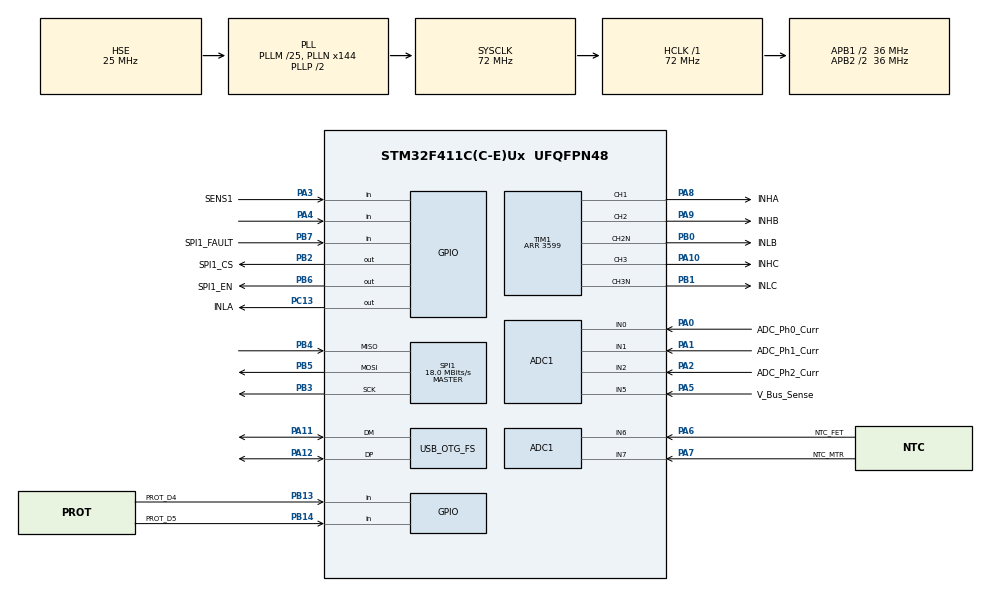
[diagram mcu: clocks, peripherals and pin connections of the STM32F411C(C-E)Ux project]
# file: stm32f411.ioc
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ADC1.Channel-0\#ChannelRegularConversion=ADC_CHANNEL_0
ADC1.Channel-1\#ChannelRegularConversion=ADC_CHANNEL_1
ADC1.Channel-2\#ChannelRegularConversion=ADC_CHANNEL_2
ADC1.Channel-3\#ChannelRegularConversion=ADC_CHANNEL_5
ADC1.Channel-4\#ChannelRegularConversion=ADC_CHANNEL_6
ADC1.Channel-5\#ChannelRegularConversion=ADC_CHANNEL_7
ADC1.ClockPrescaler=ADC_CLOCK_SYNC_PCLK_DIV4
ADC1.ContinuousConvMode=ENABLE
ADC1.DMAContinuousRequests=ENABLE
ADC1.EOCSelection=ADC_EOC_SEQ_CONV
ADC1.NbrOfConversion=6
ADC1.NbrOfConversionFlag=1
ADC1.Rank-0\#ChannelRegularConversion=1
ADC1.Rank-1\#ChannelRegularConversion=2
ADC1.Rank-2\#ChannelRegularConversion=3
ADC1.Rank-3\#ChannelRegularConversion=4
ADC1.Rank-4\#ChannelRegularConversion=5
ADC1.Rank-5\#ChannelRegularConversion=6
ADC1.SamplingTime-0\#ChannelRegularConversion=ADC_SAMPLETIME_84CYCLES
ADC1.SamplingTime-1\#ChannelRegularConversion=ADC_SAMPLETIME_84CYCLES
ADC1.SamplingTime-2\#ChannelRegularConversion=ADC_SAMPLETIME_84CYCLES
ADC1.SamplingTime-3\#ChannelRegularConversion=ADC_SAMPLETIME_84CYCLES
ADC1.SamplingTime-4\#ChannelRegularConversion=ADC_SAMPLETIME_84CYCLES
ADC1.SamplingTime-5\#ChannelRegularConversion=ADC_SAMPLETIME_84CYCLES
ADC1.ScanConvMode=ENABLE
ADC1.master=1
Dma.ADC1.0.Direction=DMA_PERIPH_TO_MEMORY
Dma.ADC1.0.FIFOMode=DMA_FIFOMODE_DISABLE
Dma.ADC1.0.Instance=DMA2_Stream0
Dma.ADC1.0.MemDataAlignment=DMA_MDATAALIGN_HALFWORD
Dma.ADC1.0.MemInc=DMA_MINC_ENABLE
Dma.ADC1.0.Mode=DMA_CIRCULAR
Dma.ADC1.0.PeriphDataAlignment=DMA_PDATAALIGN_HALFWORD
Dma.ADC1.0.PeriphInc=DMA_PINC_DISABLE
Dma.ADC1.0.Priority=DMA_PRIORITY_HIGH
Dma.Request0=ADC1
FREERTOS.Tasks01=defaultTask,24,512,StartDefaultTask,Default,NULL,Dynamic,NULL,NULL;telemTask,8,512,TelemThread,As external,NULL,Dynamic,NULL,NULL;commTask,32,1024,CommThread,As external,NULL,Dynamic,NULL,NULL
Mcu.Family=STM32F4
Mcu.Name=STM32F411C(C-E)Ux
Mcu.Package=UFQFPN48
NVIC.DMA2_Stream0_IRQn=true\:5\:0\:false\:false\:true\:true\:false\:true\:true
NVIC.OTG_FS_IRQn=true\:5\:0\:false\:false\:true\:true\:false\:true\:true
NVIC.PriorityGroup=NVIC_PRIORITYGROUP_4
NVIC.TIM5_IRQn=true\:15\:0\:false\:false\:true\:false\:false\:true\:true
NVIC.TimeBase=TIM5_IRQn
NVIC.TimeBaseIP=TIM5
PA0-WKUP.GPIO_Label=ADC_Ph0_Curr
PA0-WKUP.Signal=ADCx_IN0
PA1.GPIO_Label=ADC_Ph1_Curr
PA1.Signal=ADCx_IN1
PA10.GPIO_Label=INHC
PA10.Signal=S_TIM1_CH3
PA11.Mode=Device_Only
PA11.Signal=USB_OTG_FS_DM
PA12.Mode=Device_Only
PA12.Signal=USB_OTG_FS_DP
PA13.Mode=Serial_Wire
PA13.Signal=SYS_JTMS-SWDIO
PA14.Mode=Serial_Wire
PA14.Signal=SYS_JTCK-SWCLK
PA2.GPIO_Label=ADC_Ph2_Curr
PA2.Signal=ADCx_IN2
PA3.GPIO_Label=SENS1
PA3.Signal=GPIO_Input
PA4.Signal=GPIO_Input
PA5.GPIO_Label=V_Bus_Sense
PA5.Signal=ADCx_IN5
PA6.GPIO_Label=NTC_FET
PA6.Signal=ADCx_IN6
PA7.GPIO_Label=NTC_MTR
PA7.Signal=ADCx_IN7
PA8.GPIO_Label=INHA
PA8.Signal=S_TIM1_CH1
PA9.GPIO_Label=INHB
PA9.Signal=S_TIM1_CH2
PB0.GPIO_Label=INLB
PB0.Mode=PWM Generation2 CH2 CH2N
PB0.Signal=TIM1_CH2N
PB1.GPIO_Label=INLC
PB1.Mode=PWM Generation3 CH3 CH3N
PB1.Signal=TIM1_CH3N
PB13.GPIO_Label=PROT_D4
PB13.Signal=GPIO_Input
PB14.GPIO_Label=PROT_D5
PB14.Signal=GPIO_Input
PB2.GPIO_Label=SPI1_CS
PB2.GPIO_Speed=GPIO_SPEED_FREQ_VERY_HIGH
PB2.Signal=GPIO_Output
PB3.Mode=Full_Duplex_Master
PB3.Signal=SPI1_SCK
PB4.Mode=Full_Duplex_Master
PB4.Signal=SPI1_MISO
PB5.Mode=Full_Duplex_Master
PB5.Signal=SPI1_MOSI
PB6.GPIO_Label=SPI1_EN
PB6.GPIO_Speed=GPIO_SPEED_FREQ_VERY_HIGH
PB6.Signal=GPIO_Output
PB7.GPIO_Label=SPI1_FAULT
PB7.Signal=GPIO_Input
PC13-ANTI_TAMP.GPIO_Label=INLA
PC13-ANTI_TAMP.GPIO_Speed=GPIO_SPEED_FREQ_HIGH
PC13-ANTI_TAMP.Signal=GPIO_Output
PH0\ -\ OSC_IN.Mode=HSE-External-Oscillator
PH0\ -\ OSC_IN.Signal=RCC_OSC_IN
PH1\ -\ OSC_OUT.Mode=HSE-External-Oscillator
PH1\ -\ OSC_OUT.Signal=RCC_OSC_OUT
ProjectManager.HeapSize=0x200
ProjectManager.StackSize=0x400
ProjectManager.TargetToolchain=CMake
RCC.48MHZClocksFreq_Value=48000000
RCC.AHBFreq_Value=72000000
RCC.APB1CLKDivider=RCC_HCLK_DIV2
RCC.APB1Freq_Value=36000000
RCC.APB1TimFreq_Value=72000000
RCC.APB2CLKDivider=RCC_HCLK_DIV2
RCC.APB2Freq_Value=36000000
RCC.APB2TimFreq_Value=72000000
RCC.CortexFreq_Value=72000000
RCC.HCLKFreq_Value=72000000
RCC.HSE_VALUE=25000000
RCC.HSI_VALUE=16000000
RCC.LSE_VALUE=32768
RCC.PLLM=25
RCC.PLLN=144
RCC.PLLQ=3
RCC.SYSCLKFreq_VALUE=72000000
RCC.SYSCLKSource=RCC_SYSCLKSOURCE_PLLCLK
RCC.VCOOutputFreq_Value=144000000
SH.ADCx_IN0.0=ADC1_IN0,IN0
SH.ADCx_IN1.0=ADC1_IN1,IN1
SH.ADCx_IN2.0=ADC1_IN2,IN2
SH.ADCx_IN5.0=ADC1_IN5,IN5
SH.ADCx_IN6.0=ADC1_IN6,IN6
SH.ADCx_IN7.0=ADC1_IN7,IN7
SH.S_TIM1_CH1.0=TIM1_CH1,PWM Generation1 CH1
SH.S_TIM1_CH2.0=TIM1_CH2,PWM Generation2 CH2 CH2N
SH.S_TIM1_CH3.0=TIM1_CH3,PWM Generation3 CH3 CH3N
SPI1.CalculateBaudRate=18.0 MBits/s
SPI1.Direction=SPI_DIRECTION_2LINES
SPI1.Mode=SPI_MODE_MASTER
SPI1.VirtualType=VM_MASTER
TIM1.Channel-PWM\ Generation1\ CH1=TIM_CHANNEL_1
TIM1.Channel-PWM\ Generation2\ CH2\ CH2N=TIM_CHANNEL_2
TIM1.Channel-PWM\ Generation3\ CH3\ CH3N=TIM_CHANNEL_3
TIM1.Period=3599
TIM1.TIM_MasterOutputTrigger=TIM_TRGO_RESET
TIM1.TIM_MasterSlaveMode=TIM_MASTERSLAVEMODE_DISABLE
USB_DEVICE.CLASS_NAME_FS=CDC
USB_DEVICE.VirtualMode=Cdc
USB_DEVICE.VirtualModeFS=Cdc_FS
USB_OTG_FS.VirtualMode=Device_Only
VP_CRC_VS_CRC.Mode=CRC_Activate
VP_FREERTOS_VS_CMSIS_V2.Mode=CMSIS_V2
VP_SYS_VS_tim5.Mode=TIM5
VP_USB_DEVICE_VS_USB_DEVICE_CDC_FS.Mode=CDC_FS
board=custom

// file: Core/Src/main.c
/* USER CODE BEGIN Header */
/**
  ******************************************************************************
  * @file           : main.c
  * @brief          : Main program body
  ******************************************************************************
  * @attention
  *
  * Copyright (c) 2026 STMicroelectronics.
  * All rights reserved.
  *
  * This software is licensed under terms that can be found in the LICENSE file
  * in the root directory of this software component.
  * If no LICENSE file comes with this software, it is provided AS-IS.
  *
  ******************************************************************************
  */
/* USER CODE END Header */
#include "main.h"
#include "cmsis_os.h"
#include "usb_device.h"

/* USER CODE BEGIN Includes */
#include "bsp.h"
/* USER CODE END Includes */

ADC_HandleTypeDef hadc1;
DMA_HandleTypeDef hdma_adc1;

CRC_HandleTypeDef hcrc;

SPI_HandleTypeDef hspi1;

TIM_HandleTypeDef htim1;

/* Definitions for defaultTask */
osThreadId_t defaultTaskHandle;
const osThreadAttr_t defaultTask_attributes = {
  .name = "defaultTask",
  .stack_size = 512 * 4,
  .priority = (osPriority_t) osPriorityNormal,
};
/* Definitions for telemTask */
osThreadId_t telemTaskHandle;
const osThreadAttr_t telemTask_attributes = {
  .name = "telemTask",
  .stack_size = 512 * 4,
  .priority = (osPriority_t) osPriorityLow,
};
/* Definitions for commTask */
osThreadId_t commTaskHandle;
const osThreadAttr_t commTask_attributes = {
  .name = "commTask",
  .stack_size = 1024 * 4,
  .priority = (osPriority_t) osPriorityAboveNormal,
};

void SystemClock_Config(void);
static void MX_GPIO_Init(void);
static void MX_DMA_Init(void);
static void MX_TIM1_Init(void);
static void MX_ADC1_Init(void);
static void MX_SPI1_Init(void);
static void MX_CRC_Init(void);
void StartDefaultTask(void *argument);
extern void TelemThread(void *argument);
extern void CommThread(void *argument);

int main(void)
{

  /* MCU Configuration--------------------------------------------------------*/

  /* Reset of all peripherals, Initializes the Flash interface and the Systick. */
  HAL_Init();

  /* Configure the system clock */
  SystemClock_Config();

  /* Initialize all configured peripherals */
  MX_GPIO_Init();
  MX_DMA_Init();
  MX_TIM1_Init();
  MX_ADC1_Init();
  MX_SPI1_Init();
  MX_CRC_Init();
  /* USER CODE BEGIN 2 */
	bsp_init();
	bldc_comm_init(bsp_get_motor_handle());
  bldc_telem_init();
  // bldc_dronecan_init();
  // bldc_drv8323r_init();
  /* USER CODE END 2 */

  /* Init scheduler */
  osKernelInitialize();

  /* Create the thread(s) */
  /* creation of defaultTask */
  defaultTaskHandle = osThreadNew(StartDefaultTask, NULL, &defaultTask_attributes);

  /* creation of telemTask */
  telemTaskHandle = osThreadNew(TelemThread, NULL, &telemTask_attributes);

  /* creation of commTask */
  commTaskHandle = osThreadNew(CommThread, NULL, &commTask_attributes);

  /* Start scheduler */
  osKernelStart();

  /* We should never get here as control is now taken by the scheduler */

  /* Infinite loop */
  while (1)
  {

  }
}

void SystemClock_Config(void)
{
  RCC_OscInitTypeDef RCC_OscInitStruct = {0};
  RCC_ClkInitTypeDef RCC_ClkInitStruct = {0};

  /** Configure the main internal regulator output voltage
  */
  __HAL_RCC_PWR_CLK_ENABLE();
  __HAL_PWR_VOLTAGESCALING_CONFIG(PWR_REGULATOR_VOLTAGE_SCALE1);

  /** Initializes the RCC Oscillators according to the specified parameters
  * in the RCC_OscInitTypeDef structure.
  */
  RCC_OscInitStruct.OscillatorType = RCC_OSCILLATORTYPE_HSE;
  RCC_OscInitStruct.HSEState = RCC_HSE_ON;
  RCC_OscInitStruct.PLL.PLLState = RCC_PLL_ON;
  RCC_OscInitStruct.PLL.PLLSource = RCC_PLLSOURCE_HSE;
  RCC_OscInitStruct.PLL.PLLM = 25;
  RCC_OscInitStruct.PLL.PLLN = 144;
  RCC_OscInitStruct.PLL.PLLP = RCC_PLLP_DIV2;
  RCC_OscInitStruct.PLL.PLLQ = 3;
  if (HAL_RCC_OscConfig(&RCC_OscInitStruct) != HAL_OK)
  {
    Error_Handler();
  }

  /** Initializes the CPU, AHB and APB buses clocks
  */
  RCC_ClkInitStruct.ClockType = RCC_CLOCKTYPE_HCLK|RCC_CLOCKTYPE_SYSCLK
                              |RCC_CLOCKTYPE_PCLK1|RCC_CLOCKTYPE_PCLK2;
  RCC_ClkInitStruct.SYSCLKSource = RCC_SYSCLKSOURCE_PLLCLK;
  RCC_ClkInitStruct.AHBCLKDivider = RCC_SYSCLK_DIV1;
  RCC_ClkInitStruct.APB1CLKDivider = RCC_HCLK_DIV2;
  RCC_ClkInitStruct.APB2CLKDivider = RCC_HCLK_DIV2;

  if (HAL_RCC_ClockConfig(&RCC_ClkInitStruct, FLASH_LATENCY_2) != HAL_OK)
  {
    Error_Handler();
  }
}

static void MX_ADC1_Init(void)
{

  ADC_ChannelConfTypeDef sConfig = {0};

  /** Configure the global features of the ADC (Clock, Resolution, Data Alignment and number of conversion)
  */
  hadc1.Instance = ADC1;
  hadc1.Init.ClockPrescaler = ADC_CLOCK_SYNC_PCLK_DIV4;
  hadc1.Init.Resolution = ADC_RESOLUTION_12B;
  hadc1.Init.ScanConvMode = ENABLE;
  hadc1.Init.ContinuousConvMode = ENABLE;
  hadc1.Init.DiscontinuousConvMode = DISABLE;
  hadc1.Init.ExternalTrigConvEdge = ADC_EXTERNALTRIGCONVEDGE_NONE;
  hadc1.Init.ExternalTrigConv = ADC_SOFTWARE_START;
  hadc1.Init.DataAlign = ADC_DATAALIGN_RIGHT;
  hadc1.Init.NbrOfConversion = 6;
  hadc1.Init.DMAContinuousRequests = ENABLE;
  hadc1.Init.EOCSelection = ADC_EOC_SEQ_CONV;
  if (HAL_ADC_Init(&hadc1) != HAL_OK)
  {
    Error_Handler();
  }

  /** Configure for the selected ADC regular channel its corresponding rank in the sequencer and its sample time.
  */
  sConfig.Channel = ADC_CHANNEL_0;
  sConfig.Rank = 1;
  sConfig.SamplingTime = ADC_SAMPLETIME_84CYCLES;
  if (HAL_ADC_ConfigChannel(&hadc1, &sConfig) != HAL_OK)
  {
    Error_Handler();
  }

  /** Configure for the selected ADC regular channel its corresponding rank in the sequencer and its sample time.
  */
  sConfig.Channel = ADC_CHANNEL_1;
  sConfig.Rank = 2;
  if (HAL_ADC_ConfigChannel(&hadc1, &sConfig) != HAL_OK)
  {
    Error_Handler();
  }

  /** Configure for the selected ADC regular channel its corresponding rank in the sequencer and its sample time.
  */
  sConfig.Channel = ADC_CHANNEL_2;
  sConfig.Rank = 3;
  if (HAL_ADC_ConfigChannel(&hadc1, &sConfig) != HAL_OK)
  {
    Error_Handler();
  }

  /** Configure for the selected ADC regular channel its corresponding rank in the sequencer and its sample time.
  */
  sConfig.Channel = ADC_CHANNEL_5;
  sConfig.Rank = 4;
  if (HAL_ADC_ConfigChannel(&hadc1, &sConfig) != HAL_OK)
  {
    Error_Handler();
  }

  /** Configure for the selected ADC regular channel its corresponding rank in the sequencer and its sample time.
  */
  sConfig.Channel = ADC_CHANNEL_6;
  sConfig.Rank = 5;
  if (HAL_ADC_ConfigChannel(&hadc1, &sConfig) != HAL_OK)
  {
    Error_Handler();
  }

  /** Configure for the selected ADC regular channel its corresponding rank in the sequencer and its sample time.
  */
  sConfig.Channel = ADC_CHANNEL_7;
  sConfig.Rank = 6;
  if (HAL_ADC_ConfigChannel(&hadc1, &sConfig) != HAL_OK)
  {
    Error_Handler();
  }

}

static void MX_CRC_Init(void)
{

  hcrc.Instance = CRC;
  if (HAL_CRC_Init(&hcrc) != HAL_OK)
  {
    Error_Handler();
  }

}

static void MX_SPI1_Init(void)
{

  /* SPI1 parameter configuration*/
  hspi1.Instance = SPI1;
  hspi1.Init.Mode = SPI_MODE_MASTER;
  hspi1.Init.Direction = SPI_DIRECTION_2LINES;
  hspi1.Init.DataSize = SPI_DATASIZE_8BIT;
  hspi1.Init.CLKPolarity = SPI_POLARITY_LOW;
  hspi1.Init.CLKPhase = SPI_PHASE_1EDGE;
  hspi1.Init.NSS = SPI_NSS_SOFT;
  hspi1.Init.BaudRatePrescaler = SPI_BAUDRATEPRESCALER_2;
  hspi1.Init.FirstBit = SPI_FIRSTBIT_MSB;
  hspi1.Init.TIMode = SPI_TIMODE_DISABLE;
  hspi1.Init.CRCCalculation = SPI_CRCCALCULATION_DISABLE;
  hspi1.Init.CRCPolynomial = 10;
  if (HAL_SPI_Init(&hspi1) != HAL_OK)
  {
    Error_Handler();
  }

}

static void MX_TIM1_Init(void)
{

  TIM_MasterConfigTypeDef sMasterConfig = {0};
  TIM_OC_InitTypeDef sConfigOC = {0};
  TIM_BreakDeadTimeConfigTypeDef sBreakDeadTimeConfig = {0};

  htim1.Instance = TIM1;
  htim1.Init.Prescaler = 0;
  htim1.Init.CounterMode = TIM_COUNTERMODE_UP;
  htim1.Init.Period = 3599;
  htim1.Init.ClockDivision = TIM_CLOCKDIVISION_DIV1;
  htim1.Init.RepetitionCounter = 0;
  htim1.Init.AutoReloadPreload = TIM_AUTORELOAD_PRELOAD_DISABLE;
  if (HAL_TIM_PWM_Init(&htim1) != HAL_OK)
  {
    Error_Handler();
  }
  sMasterConfig.MasterOutputTrigger = TIM_TRGO_RESET;
  sMasterConfig.MasterSlaveMode = TIM_MASTERSLAVEMODE_DISABLE;
  if (HAL_TIMEx_MasterConfigSynchronization(&htim1, &sMasterConfig) != HAL_OK)
  {
    Error_Handler();
  }
  sConfigOC.OCMode = TIM_OCMODE_PWM1;
  sConfigOC.Pulse = 0;
  sConfigOC.OCPolarity = TIM_OCPOLARITY_HIGH;
  sConfigOC.OCNPolarity = TIM_OCNPOLARITY_HIGH;
  sConfigOC.OCFastMode = TIM_OCFAST_DISABLE;
  sConfigOC.OCIdleState = TIM_OCIDLESTATE_RESET;
  sConfigOC.OCNIdleState = TIM_OCNIDLESTATE_RESET;
  if (HAL_TIM_PWM_ConfigChannel(&htim1, &sConfigOC, TIM_CHANNEL_1) != HAL_OK)
  {
    Error_Handler();
  }
  if (HAL_TIM_PWM_ConfigChannel(&htim1, &sConfigOC, TIM_CHANNEL_2) != HAL_OK)
  {
    Error_Handler();
  }
  if (HAL_TIM_PWM_ConfigChannel(&htim1, &sConfigOC, TIM_CHANNEL_3) != HAL_OK)
  {
    Error_Handler();
  }
  sBreakDeadTimeConfig.OffStateRunMode = TIM_OSSR_DISABLE;
  sBreakDeadTimeConfig.OffStateIDLEMode = TIM_OSSI_DISABLE;
  sBreakDeadTimeConfig.LockLevel = TIM_LOCKLEVEL_OFF;
  sBreakDeadTimeConfig.DeadTime = 0;
  sBreakDeadTimeConfig.BreakState = TIM_BREAK_DISABLE;
  sBreakDeadTimeConfig.BreakPolarity = TIM_BREAKPOLARITY_HIGH;
  sBreakDeadTimeConfig.AutomaticOutput = TIM_AUTOMATICOUTPUT_DISABLE;
  if (HAL_TIMEx_ConfigBreakDeadTime(&htim1, &sBreakDeadTimeConfig) != HAL_OK)
  {
    Error_Handler();
  }
  HAL_TIM_MspPostInit(&htim1);

}

static void MX_DMA_Init(void)
{

  /* DMA controller clock enable */
  __HAL_RCC_DMA2_CLK_ENABLE();

  /* DMA interrupt init */
  /* DMA2_Stream0_IRQn interrupt configuration */
  HAL_NVIC_SetPriority(DMA2_Stream0_IRQn, 5, 0);
  HAL_NVIC_EnableIRQ(DMA2_Stream0_IRQn);

}

static void MX_GPIO_Init(void)
{
  GPIO_InitTypeDef GPIO_InitStruct = {0};

  /* GPIO Ports Clock Enable */
  __HAL_RCC_GPIOC_CLK_ENABLE();
  __HAL_RCC_GPIOH_CLK_ENABLE();
  __HAL_RCC_GPIOA_CLK_ENABLE();
  __HAL_RCC_GPIOB_CLK_ENABLE();

  /*Configure GPIO pin Output Level */
  HAL_GPIO_WritePin(INLA_GPIO_Port, INLA_Pin, GPIO_PIN_RESET);

  /*Configure GPIO pin Output Level */
  HAL_GPIO_WritePin(GPIOB, SPI1_CS_Pin|SPI1_EN_Pin, GPIO_PIN_RESET);

  /*Configure GPIO pin : INLA_Pin */
  GPIO_InitStruct.Pin = INLA_Pin;
  GPIO_InitStruct.Mode = GPIO_MODE_OUTPUT_PP;
  GPIO_InitStruct.Pull = GPIO_NOPULL;
  GPIO_InitStruct.Speed = GPIO_SPEED_FREQ_HIGH;
  HAL_GPIO_Init(INLA_GPIO_Port, &GPIO_InitStruct);

  /*Configure GPIO pins : SENS1_Pin PA4 */
  GPIO_InitStruct.Pin = SENS1_Pin|GPIO_PIN_4;
  GPIO_InitStruct.Mode = GPIO_MODE_INPUT;
  GPIO_InitStruct.Pull = GPIO_NOPULL;
  HAL_GPIO_Init(GPIOA, &GPIO_InitStruct);

  /*Configure GPIO pins : SPI1_CS_Pin SPI1_EN_Pin */
  GPIO_InitStruct.Pin = SPI1_CS_Pin|SPI1_EN_Pin;
  GPIO_InitStruct.Mode = GPIO_MODE_OUTPUT_PP;
  GPIO_InitStruct.Pull = GPIO_NOPULL;
  GPIO_InitStruct.Speed = GPIO_SPEED_FREQ_VERY_HIGH;
  HAL_GPIO_Init(GPIOB, &GPIO_InitStruct);

  /*Configure GPIO pins : PROT_D4_Pin PROT_D5_Pin SPI1_FAULT_Pin */
  GPIO_InitStruct.Pin = PROT_D4_Pin|PROT_D5_Pin|SPI1_FAULT_Pin;
  GPIO_InitStruct.Mode = GPIO_MODE_INPUT;
  GPIO_InitStruct.Pull = GPIO_NOPULL;
  HAL_GPIO_Init(GPIOB, &GPIO_InitStruct);

}

void StartDefaultTask(void *argument)
{
  /* init code for USB_DEVICE */
  MX_USB_DEVICE_Init();
  /* USER CODE BEGIN 5 */
  /* Infinite loop */
  for(;;)
  {
		osDelay(10);
	}
  /* USER CODE END 5 */
}

void HAL_TIM_PeriodElapsedCallback(TIM_HandleTypeDef *htim)
{
  if (htim->Instance == TIM5)
  {
    HAL_IncTick();
  }
  /* USER CODE BEGIN Callback 1 */
#if CONFIG_FOC_ENABLE
  extern void bldc_foc_hal_period_callback(TIM_HandleTypeDef *htim);
  bldc_foc_hal_period_callback(htim);
#endif
  /* USER CODE END Callback 1 */
}

void Error_Handler(void)
{
  __disable_irq();
  while (1)
  {
  }
}
